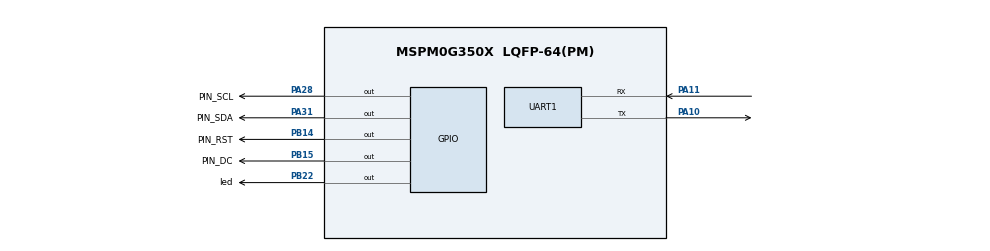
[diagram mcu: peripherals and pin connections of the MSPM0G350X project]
/**
 * @cliArgs --device "MSPM0G350X" --part "Default" --package "LQFP-64(PM)" --product "mspm0_sdk@2.05.01.00"
 * @versions {"tool":"1.24.1+4189"}
 */

/**
 * Import the modules used in this configuration.
 */
const GPIO    = scripting.addModule("/ti/driverlib/GPIO", {}, false);
const GPIO1   = GPIO.addInstance();
const GPIO2   = GPIO.addInstance();
const GPIO3   = GPIO.addInstance();
const GPIO4   = GPIO.addInstance();
const GPIO5   = GPIO.addInstance();
const SYSCTL  = scripting.addModule("/ti/driverlib/SYSCTL");
const SYSTICK = scripting.addModule("/ti/driverlib/SYSTICK");
const UART    = scripting.addModule("/ti/driverlib/UART", {}, false);
const UART1   = UART.addInstance();

/**
 * Write custom configuration values to the imported modules.
 */
const divider7       = system.clockTree["PLL_PDIV"];
divider7.divideValue = 2;

const divider9       = system.clockTree["UDIV"];
divider9.divideValue = 2;

const multiplier2         = system.clockTree["PLL_QDIV"];
multiplier2.multiplyValue = 5;

const mux8       = system.clockTree["HSCLKMUX"];
mux8.inputSelect = "HSCLKMUX_SYSPLL2X";

GPIO1.$name                         = "OLED_RST";
GPIO1.associatedPins[0].$name       = "PIN_RST";
GPIO1.associatedPins[0].pin.$assign = "PB14";

const Board = scripting.addModule("/ti/driverlib/Board", {}, false);

GPIO2.$name                         = "OLED_DC";
GPIO2.associatedPins[0].$name       = "PIN_DC";
GPIO2.associatedPins[0].pin.$assign = "PB15";

GPIO3.$name                         = "OLED_SCL";
GPIO3.associatedPins[0].$name       = "PIN_SCL";
GPIO3.associatedPins[0].pin.$assign = "PA28";

GPIO4.$name                         = "OLED_SDA";
GPIO4.associatedPins[0].$name       = "PIN_SDA";
GPIO4.associatedPins[0].pin.$assign = "PA31";

GPIO5.$name                         = "LED";
GPIO5.port                          = "PORTB";
GPIO5.associatedPins[0].$name       = "led";
GPIO5.associatedPins[0].assignedPin = "22";
GPIO5.associatedPins[0].pin.$assign = "PB22";

SYSCTL.forceDefaultClkConfig = true;
SYSCTL.clockTreeEn           = true;

SYSTICK.periodEnable  = true;
SYSTICK.systickEnable = true;
SYSTICK.period        = 16777216;

UART1.$name                    = "UART_0";
UART1.profile                  = "CONFIG_PROFILE_1";
UART1.peripheral.rxPin.$assign = "PA11";
UART1.peripheral.txPin.$assign = "PA10";
UART1.txPinConfig.$name        = "ti_driverlib_gpio_GPIOPinGeneric2";
UART1.rxPinConfig.$name        = "ti_driverlib_gpio_GPIOPinGeneric3";

/**
 * Pinmux solution for unlocked pins/peripherals. This ensures that minor changes to the automatic solver in a future
 * version of the tool will not impact the pinmux you originally saw.  These lines can be completely deleted in order to
 * re-solve from scratch.
 */
Board.peripheral.$suggestSolution          = "DEBUGSS";
Board.peripheral.swclkPin.$suggestSolution = "PA20";
Board.peripheral.swdioPin.$suggestSolution = "PA19";
UART1.peripheral.$suggestSolution          = "UART0";
